# gcr_me10 register map
Registers are access not given, no defined reset value unless marked. A register's access mark holds for its fields unless they carry their own. Offsets are from the block's base; lines under a group give offsets from that group; [hi:lo] are bit positions; {n}, {i} and the like mark numbered series; 'fields as' and 'values as' point back to an identical list; <NAME> marks a mode.

## Memory map
0x40000000 GCR size 0x400 — Global Control Registers.

## GCR — Global Control Registers.
Base 0x40000000
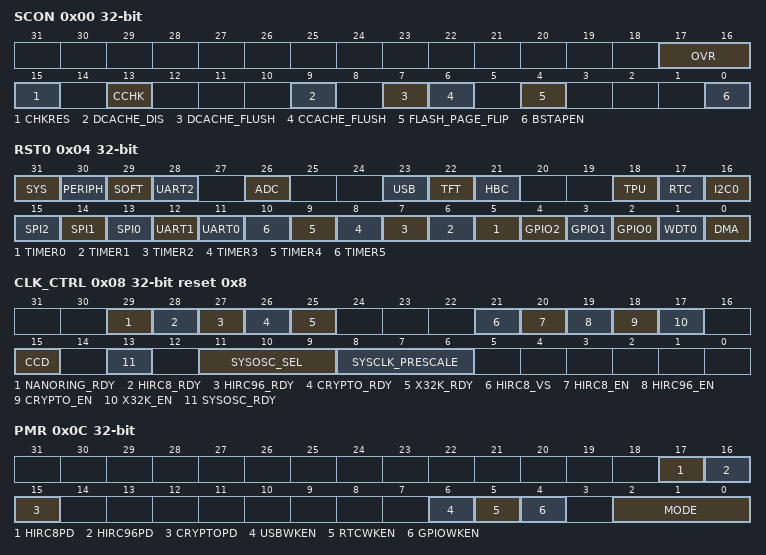
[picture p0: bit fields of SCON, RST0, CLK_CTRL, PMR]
0x00 SCON — System Control.
  [17:16] OVR — These bits select the operating voltage range.
    0=0v9 (0.9V +/- 10%.); 1=1V (1.0V +/- 10%.); 2=1V1 (1.1V +/- 10%.)
  [15] CHKRES — ROM Checksum Result. This bit is only valid when CHKRD=1.
    0=pass (ROM Checksum Correct.); 1=fail (ROM Checksum Fail.)
  [13] CCHK — Compute ROM Checksum. This bit is self-cleared when calculation is completed. Once set, software clearing this bit is ignored and the bit will remain set until the operation is completed.
    0=complete (No operation/complete.); 1=Start operation
  [9] DCACHE_DIS — Disable EMCC used for SPIXR or HyperBus/Xccela Bus code and data cache.
    0=enabled (EMCC enabled.); 1=disabled (EMCC disabled and line buffer bypassed.)
  [7] DCACHE_FLUSH — Write 1 to flush the external memory controller's 16KB cache. This bit is automatically cleared to 0 when the flush is complete.
    0=Normal External Cache Operation; 1=flush (External cache being flushed.)
  [6] CCACHE_FLUSH — Code Cache Flush. This bit is used to flush the code caches and the instruction buffer of the Cortex-M4.
    0=Normal Code Cache Operation; 1=flush (Code Caches and CPU instruction buffer are flushed)
  [4] FLASH_PAGE_FLIP — Flips the Flash bottom and top halves. (Depending on the total flash size, each half is either 256K or 512K). Initiating a flash page flip will cause a flush of both the data buffer on the DCODE bus and the internal instruction buffer.
    0=normal (Physical layout matches logical layout.); 1=flipped (Bottom half mapped to logical top half and vice versa.)
  [0] BSTAPEN — Boundary Scan TAP enable. When enabled, the JTAG port is connected to the Boundary Scan TAP. Otherwise, the port is connected to the ARM ICE function. This bit is reset by the POR. Reset value and access depend on the part number.
    0=dis (Boundary Scan TAP port disabled.); 1=en (Boundary Scan TAP port enabled.)
0x04 RST0 — Reset.
  [31] SYS — System Reset. Setting this bit to 1 resets the CPU core and all peripherals, including the watchdog timer.
  [30] PERIPH — Peripheral Reset. Setting this bit to 1 resets all peripherals. The CPU core, the watchdog timer, and all GPIO pins are unaffected by this reset.
  [29] SOFT — Soft Reset. Setting this bit to 1 resets everything except the CPU and the watchdog timer.
  [28] UART2 — UART 2 reset.
  [26] ADC — Analog to Digital converter reset.
  [23] USB — USB Reset.
  [22] TFT — TFT controller reset.
  [21] HBC — HyperBus/Xccela controller reset.
  [18] TPU — Trust Protection Unit Reset. Setting this bit to 1 resets the AES block, the SHA block and the DES block.
  [17] RTC — RTC Reset.
  [16] I2C0 — I2C0 Reset.
  [15] SPI2 — SPI2 Reset. Setting this bit to 1 resets all SPI 2 blocks.
  [14] SPI1 — SPI1 Reset. Setting this bit to 1 resets all SPI 1 blocks.
  [13] SPI0 — SPI0 Reset. Setting this bit to 1 resets all SPI 0 blocks.
  [12] UART1 — UART1 Reset. Setting this bit to 1 resets all UART 1 blocks.
  [11] UART0 — UART0 Reset. Setting this bit to 1 resets all UART 0 blocks.
  [n+5] TIMER{n} (n=0..5) — Timer{n} Reset. Setting this bit to 1 resets Timer {n} blocks.
  [4] GPIO2 — GPIO2 Reset. Setting this bit to 1 resets GPIO2 pins to their default states.
  [3] GPIO1 — GPIO1 Reset. Setting this bit to 1 resets GPIO1 pins to their default states.
  [2] GPIO0 — GPIO0 Reset. Setting this bit to 1 resets GPIO0 pins to their default states.
  [1] WDT0 — Watchdog Timer Reset.
  [0] DMA — DMA Reset.
0x08 CLK_CTRL reset 0x8 — Clock Control.
  [29] NANORING_RDY — Internal Nano Ring Oscillator Low Frequency Reference Clock Ready.
  [28] HIRC8_RDY — 7.3728MHz Internal Oscillator Ready.
  [27] HIRC96_RDY — 120MHz Internal Oscillator Ready.
  [26] CRYPTO_RDY — 50MHz Internal Oscillator Ready.
  [25] X32K_RDY — 32KHz External Oscillator Ready.
  [21] HIRC8_VS — 7.3728MHz Internal Oscillator Voltage Source Select
  [20] HIRC8_EN — 7.3728MHz High Frequency Internal Reference Clock Enable.
  [19] HIRC96_EN — 120MHz High Frequency Internal Reference Clock Enable.
  [18] CRYPTO_EN — 50MHz High Frequency Internal Reference Clock Enable.
  [17] X32K_EN — 32KHz External Clock Enable.
  [15] CCD ro — Cryptographic clock divider
    0=non_div (The cryptographic accelerator clock is running in non-divided mode.); 1=div (The cryptographic accelerator clock is running in divided mode.)
  [13] SYSOSC_RDY ro — Clock Ready. This read only bit reflects whether the currently selected system clock source is running.
    0=busy (Switchover to the new clock source (as selected by CLKSEL) has not yet occurred.); 1=ready (System clock running from CLKSEL clock source.)
  [11:9] SYSOSC_SEL — Clock Source Select. This 3 bit field selects the source for the system clock.
    0=CRYPTO (Internal Primary Oscilatior Clock); 2=HFXIN (24MHz Internal Oscillator is used for the system clock.); 3=NANORING (8kHz Internal Nano Ring Oscillator is used for the system clock.); 4=HIRC96 (120 MHz Internal Oscillator.); 5=HIRC8 (Internal 7.3728MHz oscillator.); 6=X32K (External 32KHz oscillator.)
  [8:6] SYSCLK_PRESCALE — Prescaler Select. This 3 bit field sets the system operating frequency by controlling the prescaler that divides the output of the PLL0.
    0=div1 (Divide by 1.); 1=div2 (Divide by 2.); 2=div4 (Divide by 4.); 3=div8 (Divide by 8.); 4=div16 (Divide by 16.); 5=div32 (Divide by 32.); 6=div64 (Divide by 64.); 7=div128 (Divide by 128.)
0x0C PMR — Power Management.
  [17] HIRC8PD — 7.3728MHz Internal Oscillator power down. This bit selects whether the oscillator is automatically powered down when the device transitions to DEEPSLEEP mode.
    0=active (Mode is Active.); 1=deepsleep (Powered down in DEEPSLEEP.)
  [16] HIRC96PD — 120MHz Internal Oscillator power down. This bit selects whether the oscillator is automatically powered down when the device transitions to DEEPSLEEP mode.
    values as HIRC8PD
  [15] CRYPTOPD — Crypto Oscilator Power Down. This bit selects whether the oscillator is automatically powered down when the device transitions to DEEPSLEEP mode.
    values as HIRC8PD
  [6] USBWKEN — USB Wake Up Enable. This enables a USB wakeup event to cause the device to exit from all low power modes into ACTIVE mode.
  [5] RTCWKEN — RTC Wake Up Enable. This bit enables an RTC alarm to wake the device from any low-power mode to ACTIVE mode.
  [4] GPIOWKEN — GPIO Wake Up Enable. This bit enables all GPIO pins as potential wakeup sources. Any GPIO configured for wakeup is capable of causing an exit from IDLE or STANDBY modes when this bit is set.
  [2:0] MODE — Operating Mode. This two bit field selects the current operating mode for the device. Note that code execution only occurs during ACTIVE mode.
    0=Active Mode; 3=Shutdown Mode; 4=Backup Mode
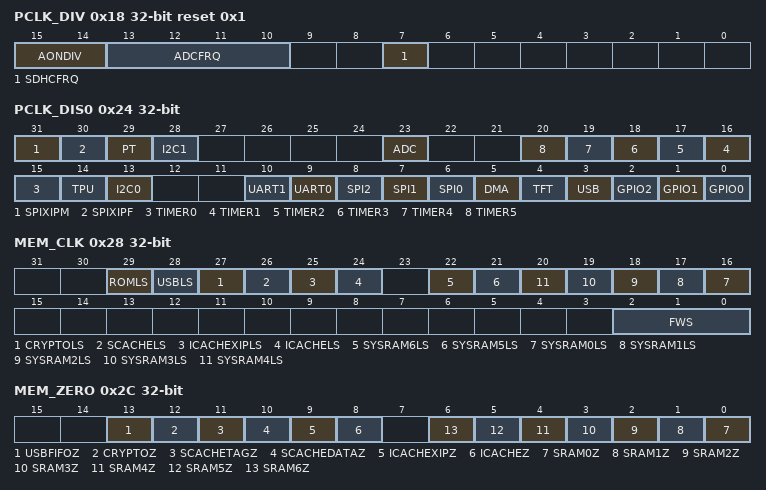
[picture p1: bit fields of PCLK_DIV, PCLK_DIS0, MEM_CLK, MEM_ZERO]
0x18 PCLK_DIV reset 0x1 — Peripheral Clock Divider.
  [15:14] AONDIV — Always-ON (AON) domain CLock Divider. These bits define the AON domain clock divider.
    0=div4 (PCLK divide by 4.); 1=div8 (PCLK divide by 8.); 2=div16 (PCLK divide by 16.); 3=div32 (PCLK divide by 32.)
  [13:10] ADCFRQ — ADC Clock divider. ADC Clock Frequency = Periph_Clock/adcfrq. Values 0 and 1 invalid.
    {v}=div{v} (ADC Freq = Periph_Clock/{v}.) (v=2..15)
  [7] SDHCFRQ — This bit selects the frequency of the SDHC clock. If set, the clock oscillates at 50Mhz, otherwise it will oscillate at 60MHz.
    0=60M (SDHC Freq = 120MHz/2.); 1=50M (SDHC Freq = 50Mhz.)
0x24 PCLK_DIS0 — Peripheral Clock Disable.
  [all] fields
    0=en (enable it.); 1=dis (disable it.)
  [31] SPIXIPM — XSPI Master Clock Disable.
  [30] SPIXIPF — SPI-XIPF Disable.
  [29] PT — Pulse Train Engine Disable.
  [28] I2C1 — I2C 1 Disable.
  [23] ADC — ADC Disable.
  [n+15] TIMER{n} (n=0..5) — Timer {n} Disable.
  [14] TPU — Trust Protection Unit Disable.
  [13] I2C0 — I2C 0 Disable.
  [10] UART1 — UART 1 Disable.
  [9] UART0 — UART 0 Disable.
  [8] SPI2 — SPI 2 Disable.
  [7] SPI1 — SPI 1 Disable.
  [6] SPI0 — SPI 0 Disable.
  [5] DMA — DMA Disable.
  [4] TFT — TFT Disable.
  [3] USB — USB Disable.
  [2] GPIO2 — GPIO2 Disable.
  [1] GPIO1 — GPIO1 Disable.
  [0] GPIO0 — GPIO0 Clock Disable.
0x28 MEM_CLK — Memory Clock Control Register.
  [29] ROMLS — ROM Light Sleep Mode.
    0=active (RAM is active.); 1=light_sleep (RAM is in Light Sleep mode.)
  [28] USBLS — USB FIFO Light Sleep Mode.
    values as ROMLS
  [27] CRYPTOLS — Crypto RAM Light Sleep Mode.
    values as ROMLS
  [26] SCACHELS — Internal RAM Cache Light Sleep Mode.
    values as ROMLS
  [25] ICACHEXIPLS — SPI-XIPF Instruction Cache RAM Light Sleep Mode.
    values as ROMLS
  [24] ICACHELS — ICache RAM Light Sleep Mode.
    values as ROMLS
  [22] SYSRAM6LS — System RAM 4 Light Sleep Mode. Write 1 to put RAM6 in light sleep power mode.
    values as ROMLS
  [21] SYSRAM5LS — System RAM 4 Light Sleep Mode. Write 1 to put RAM5 in light sleep power mode.
    values as ROMLS
  [n+16] SYSRAM{n}LS (n=0..4) — System RAM {n} Light Sleep Mode. Write 1 to put RAM{n} in light sleep power mode.
    values as ROMLS
  [2:0] FWS — Flash Wait State. These bits define the number of wait-state cycles per Flash data read access. Minimum wait state is 1.
0x2C MEM_ZERO — Memory Zeroize Control.
  [all] fields
    0=nop (No operation/complete.); 1=Start operation
  [13] USBFIFOZ — USB FIFO zeroization.
  [12] CRYPTOZ — Crypto MAA Memory zeroization.
  [11] SCACHETAGZ — EMCC tag zeroization.
  [10] SCACHEDATAZ — EMCC data zeroization.
  [9] ICACHEXIPZ — SPI-XIPF Instruction Cache (ICC1) zeroization.
  [8] ICACHEZ — Instruction Cache (ICC0) zeroization.
  [n] SRAM{n}Z (n=0..6) — System RAM Block {n}.
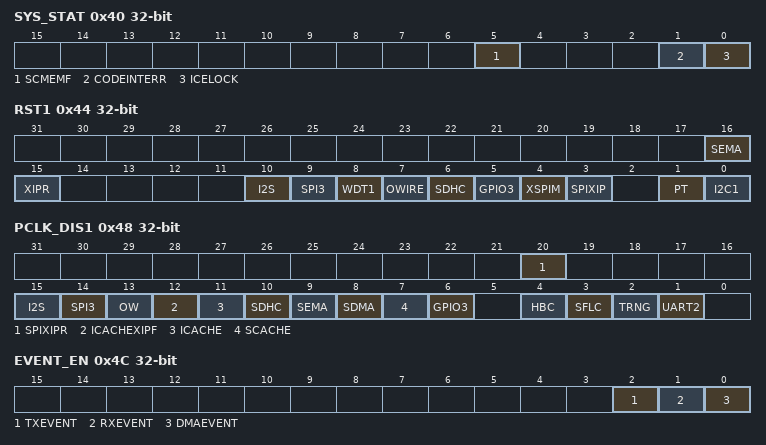
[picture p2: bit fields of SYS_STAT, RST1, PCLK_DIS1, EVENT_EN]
0x40 SYS_STAT — System Status Register.
  [5] SCMEMF — HyperBus/Xccela Cache Memory Error Status Flag.
    0=noerr (Normal operation.); 1=memfault (HyperBus/Xccela cahce memory fault.)
  [1] CODEINTERR — Flash SPI-XIPF Code Integrity Error Status Flag.
    0=noerr; 1=err (SPI-XIPF code integrity error.)
  [0] ICELOCK — ARM ICE Lock Status.
    0=unlocked (ICE is unlocked.); 1=locked (ICE is locked.)
0x44 RST1 — Reset 1.
  [16] SEMA — Semaphore Block Reset.
  [15] XIPR — SPIXR Reset.
  [10] I2S — I2S (SPIMSS) Reset.
  [9] SPI3 — SPI3 Reset.
  [8] WDT1 — WDT1 Reset.
  [7] OWIRE — One-Wire Reset.
  [6] SDHC — SDHC Reset.
  [5] GPIO3 — GPIO3 Reset.
  [4] XSPIM — XSPI Master Reset.
  [3] SPIXIP — SPI-XIPF Reset.
  [1] PT — Pulse Train Reset.
  [0] I2C1 — I2C1 Reset.
0x48 PCLK_DIS1 — Peripheral Clock Disable.
  [all] fields
    0=en (Clock enabled to the peripheral.); 1=dis (Clock disabled to the peripheral.)
  [20] SPIXIPR — SPIXR RAM Clock Disable.
  [15] I2S — I2S (SPIMSS) Clock Disable.
  [14] SPI3 — SPI3 Clock Disable.
  [13] OW — One-Wire Clock Disable.
  [12] ICACHEXIPF — SPI-XIPF Flash Clock Disable.
  [11] ICACHE — Flash Instruction Cache Clock Disable.
  [10] SDHC — SDHC Controller Clock Disable.
  [9] SEMA — Semaphore Block Clock Disable.
  [8] SDMA — Smart DMA Clock Disable.
  [7] SCACHE — System Cache Clock Disable.
  [6] GPIO3 — GPIO3 Disable.
  [4] HBC — HyperBus/Xccela Clock Disable.
  [3] SFLC — Secore Flash Controller Clock Disable.
  [2] TRNG — TRNG Disable.
  [1] UART2 — UART2 Disable.
0x4C EVENT_EN — Event Enable Register.
  [2] TXEVENT — Enable TXEV pin event. When this bit is set, TXEV event from the CPU is output to GPIO[25].
    0=dis (Transmit event disabled.); 1=en (A transmit event is enabled on Send Event instruction.)
  [1] RXEVENT — Enable RXEV pin event. When this bit is set, a logic high of GPIO0[24] will cause an RXEV event to wake the CPU from WFE sleep mode.
    0=dis (A receive event is not generated when an external input transitions from low to high.); 1=en (A receive event is generated when external event is triggered.)
  [0] DMAEVENT — Enable DMA event. When this bit is set, a DMA event will cause an RXEV event to wake the CPU from WFE sleep mode.
    0=dis (DMA CTZ Event will not wake up the device.); 1=en (DMA CTZ Event Wake-up Enabled.)
0x50 REV ro — Revision Register.
  [15:0] REVISION — Manufacturer Chip Revision.
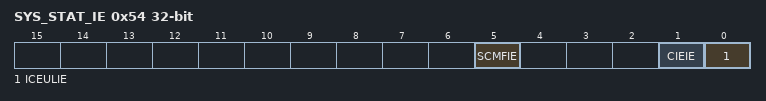
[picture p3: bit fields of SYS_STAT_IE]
0x54 SYS_STAT_IE — System Status Interrupt Enable Register.
  [all] fields
    0=dis (disabled.); 1=en (enabled.)
  [5] SCMFIE — HyperBus/Xccela Cache Memory Fault Interrupt Enable.
  [1] CIEIE — SPI-XIPF Code Intergrity Error Interrupt Enable.
  [0] ICEULIE — ARM ICE Unlock Interrupt Enable.
